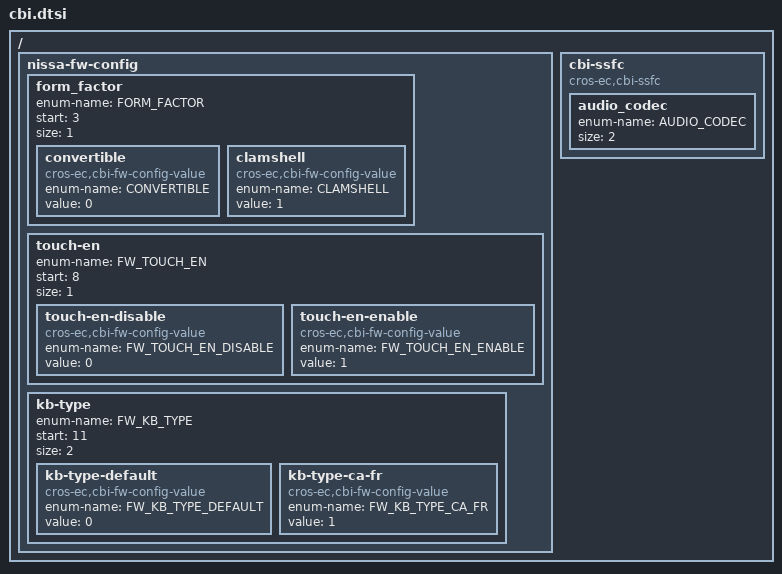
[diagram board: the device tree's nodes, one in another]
/* Copyright 2024 The ChromiumOS Authors
 * Use of this source code is governed by a BSD-style license that can be
 * found in the LICENSE file.
 */

/ {
	/* Craask-specific fw_config fields. */
	nissa-fw-config {
		/*
		 * FW_CONFIG field to describe Clamshell/Convertible.
		 */
		form_factor {
			enum-name = "FORM_FACTOR";
			start = <3>;
			size = <1>;

			/*
			 * 0: convertible, 1: clamshell
			 */
			convertible {
				compatible = "cros-ec,cbi-fw-config-value";
				enum-name = "CONVERTIBLE";
				value = <0>;
			};
			clamshell {
				compatible = "cros-ec,cbi-fw-config-value";
				enum-name = "CLAMSHELL";
				value = <1>;
			};
		};

		/*
		 * FW_CONFIG field to enable touch panel power sequence
		 * control or not.
		 */
		touch-en {
			enum-name = "FW_TOUCH_EN";
			start = <8>;
			size = <1>;

			touch-en-disable {
				compatible = "cros-ec,cbi-fw-config-value";
				enum-name = "FW_TOUCH_EN_DISABLE";
				value = <0>;
			};
			touch-en-enable {
				compatible = "cros-ec,cbi-fw-config-value";
				enum-name = "FW_TOUCH_EN_ENABLE";
				value = <1>;
			};
		};

		/*
		 * FW_CONFIG field to change scancode setting for special
		 * keyboard type.
		 */
		kb-type {
			enum-name = "FW_KB_TYPE";
			start = <11>;
			size = <2>;

			kb-type-default {
				compatible = "cros-ec,cbi-fw-config-value";
				enum-name = "FW_KB_TYPE_DEFAULT";
				value = <0>;
			};
			kb-type-ca-fr {
				compatible = "cros-ec,cbi-fw-config-value";
				enum-name = "FW_KB_TYPE_CA_FR";
				value = <1>;
			};
		};

	};
	/* Craask-specific ssfc fields. */
	cbi-ssfc {
		compatible = "cros-ec,cbi-ssfc";
		/*
		 * SSFC bit0-1 was defined for AUDIO CODEC.
		 * 0: ALC5682I_VS
		 * 1: NAU8825
		 */
		audio_codec {
			enum-name = "AUDIO_CODEC";
			size = <2>;
		};
	};
};
